AUTOSAR XML (schema 4-0-3)
package /ComponentTypes
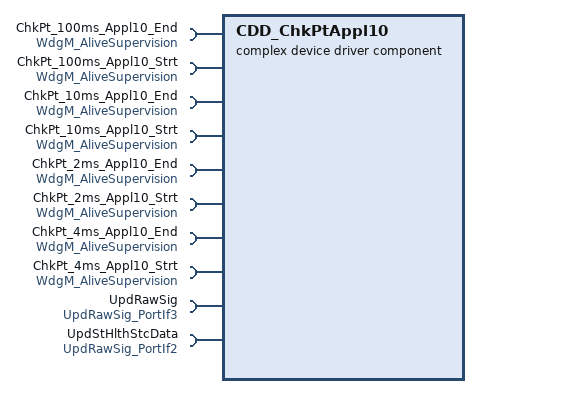
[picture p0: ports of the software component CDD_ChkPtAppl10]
  complex device driver sw component type CDD_ChkPtAppl10
    10 x require port:
      ChkPt_100ms_Appl10_End: required-interface=WdgM_AliveSupervision
      ChkPt_100ms_Appl10_Strt: required-interface=WdgM_AliveSupervision
      ChkPt_10ms_Appl10_End: required-interface=WdgM_AliveSupervision
      ChkPt_10ms_Appl10_Strt: required-interface=WdgM_AliveSupervision
      ChkPt_2ms_Appl10_End: required-interface=WdgM_AliveSupervision
      ChkPt_2ms_Appl10_Strt: required-interface=WdgM_AliveSupervision
      ChkPt_4ms_Appl10_End: required-interface=WdgM_AliveSupervision
      ChkPt_4ms_Appl10_Strt: required-interface=WdgM_AliveSupervision
      UpdRawSig: required-interface=UpdRawSig_PortIf3
      UpdStHlthStcData: required-interface=UpdRawSig_PortIf2
    behavior CDD_ChkPtAppl10_InternalBehavior
      8 x timing event:
        TMT_ChkPt_100msAppl10End: start-on-event=ChkPt_100msAppl10End, period=0.1
        TMT_ChkPt_100msAppl10Strt: start-on-event=ChkPt_100msAppl10Strt, period=0.1
        TMT_ChkPt_10msAppl10End: start-on-event=ChkPt_10msAppl10End, period=0.01
        TMT_ChkPt_10msAppl10Strt: start-on-event=ChkPt_10msAppl10Strt, period=0.01
        TMT_ChkPt_2msAppl10End: start-on-event=ChkPt_2msAppl10End, period=0.002
        TMT_ChkPt_2msAppl10Strt: start-on-event=ChkPt_2msAppl10Strt, period=0.002
        TMT_ChkPt_4msAppl10End: start-on-event=ChkPt_4msAppl10End, period=0.004
        TMT_ChkPt_4msAppl10Strt: start-on-event=ChkPt_4msAppl10Strt, period=0.004
      8 x runnable:
        ChkPt_100msAppl10End
          sync call SC_ChkPt_100ms_Appl10_End_CheckpointReached: operation=ChkPt_100ms_Appl10_End.CheckpointReached, timeout=0
          sync call SC_UpdRawSig_Oper: operation=UpdRawSig.Oper, timeout=0
          sync call SC_UpdStHlthStcData_Oper: operation=UpdStHlthStcData.Oper, timeout=0
        ChkPt_100msAppl10Strt
          sync call SC_ChkPt_100ms_Appl10_Strt_CheckpointReached: operation=ChkPt_100ms_Appl10_Strt.CheckpointReached, timeout=0
        ChkPt_10msAppl10End
          sync call SC_ChkPt_10ms_Appl10_End_CheckpointReached: operation=ChkPt_10ms_Appl10_End.CheckpointReached, timeout=0
          sync call SC_UpdRawSig_Oper: operation=UpdRawSig.Oper, timeout=0
          sync call SC_UpdStHlthStcData_Oper: operation=UpdStHlthStcData.Oper, timeout=0
        ChkPt_10msAppl10Strt
          sync call SC_ChkPt_10ms_Appl10_Strt_CheckpointReached: operation=ChkPt_10ms_Appl10_Strt.CheckpointReached, timeout=0
        ChkPt_2msAppl10End
          sync call SC_ChkPt_2ms_Appl10_End_CheckpointReached: operation=ChkPt_2ms_Appl10_End.CheckpointReached, timeout=0
          sync call SC_UpdRawSig_Oper: operation=UpdRawSig.Oper, timeout=0
          sync call SC_UpdStHlthStcData_Oper: operation=UpdStHlthStcData.Oper, timeout=0
        ChkPt_2msAppl10Strt
          sync call SC_ChkPt_2ms_Appl10_Strt_CheckpointReached: operation=ChkPt_2ms_Appl10_Strt.CheckpointReached, timeout=0
        ChkPt_4msAppl10End
          sync call SC_ChkPt_4ms_Appl10_End_CheckpointReached: operation=ChkPt_4ms_Appl10_End.CheckpointReached, timeout=0
          sync call SC_UpdRawSig_Oper: operation=UpdRawSig.Oper, timeout=0
          sync call SC_UpdStHlthStcData_Oper: operation=UpdStHlthStcData.Oper, timeout=0
        ChkPt_4msAppl10Strt
          sync call SC_ChkPt_4ms_Appl10_Strt_CheckpointReached: operation=ChkPt_4ms_Appl10_Strt.CheckpointReached, timeout=0
  swc implementation CDD_ChkPtAppl10_Implementation: behavior=CDD_ChkPtAppl10_InternalBehavior
    code-descriptors:
      code Default: artifact-descriptors=autosar-engineering-object={short-label=Default, category=SWSRC}
